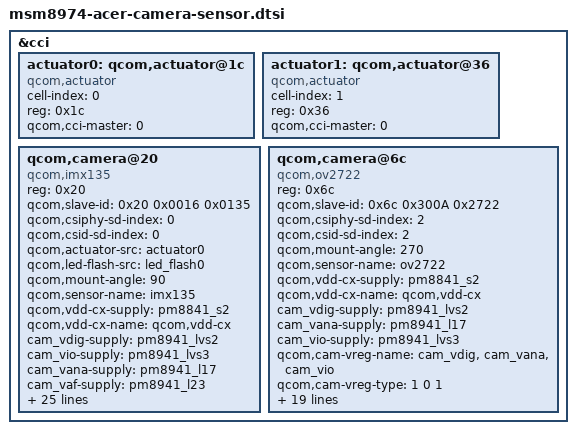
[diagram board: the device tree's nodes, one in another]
/*
 * Copyright (c) 2012-2013, The Linux Foundation. All rights reserved.
 *
 * This program is free software; you can redistribute it and/or modify
 * it under the terms of the GNU General Public License version 2 and
 * only version 2 as published by the Free Software Foundation.
 *
 * This program is distributed in the hope that it will be useful,
 * but WITHOUT ANY WARRANTY; without even the implied warranty of
 * MERCHANTABILITY or FITNESS FOR A PARTICULAR PURPOSE.  See the
 * GNU General Public License for more details.
 */

&cci {

	actuator0: qcom,actuator@1c {
		cell-index = <0>;
		reg = <0x1c>;
		compatible = "qcom,actuator";
		qcom,cci-master = <0>;
	};

	actuator1: qcom,actuator@36 {
		cell-index = <1>;
		reg = <0x36>;
		compatible = "qcom,actuator";
		qcom,cci-master = <0>;
	};

	qcom,camera@20 {
		compatible = "qcom,imx135";
		reg = <0x20>;
		qcom,slave-id = <0x20 0x0016 0x0135>;
		qcom,csiphy-sd-index = <0>;
		qcom,csid-sd-index = <0>;
		qcom,actuator-src = <&actuator0>;
		qcom,led-flash-src = <&led_flash0>;
		qcom,mount-angle = <90>;
		qcom,sensor-name = "imx135";
		qcom,vdd-cx-supply = <&pm8841_s2>;
		qcom,vdd-cx-name = "qcom,vdd-cx";
		cam_vdig-supply = <&pm8941_lvs2>;
		cam_vio-supply = <&pm8941_lvs3>;
		cam_vana-supply = <&pm8941_l17>;
		cam_vaf-supply = <&pm8941_l23>;
		cam_vif-supply = <&pm8941_l3>;
		qcom,cam-vreg-name = "cam_vdig", "cam_vio", "cam_vana",
				     "cam_vaf", "cam_vif";
		qcom,cam-vreg-type = <1 1 0 0 0>;
		qcom,cam-vreg-min-voltage = <0 0 2850000 2800000 1100000>;
		qcom,cam-vreg-max-voltage = <0 0 2850000 2800000 1225000>;
		qcom,cam-vreg-op-mode = <0 0 2850000 2800000 1100000>;
		qcom,gpio-no-mux = <0>;
		gpios = <&msmgpio 15 0>,
			<&msmgpio 89 0>;
		qcom,gpio-reset = <1>;
		qcom,gpio-req-tbl-num = <0 1>;
		qcom,gpio-req-tbl-flags = <1 0>;
		qcom,gpio-req-tbl-label = "CAMIF_MCLK",
					  "CAM_RESET1";
		qcom,gpio-set-tbl-num = <1 1>;
		qcom,gpio-set-tbl-flags = <0 2>;
		qcom,gpio-set-tbl-delay = <1000 30000>;
		qcom,csi-lane-assign = <0x4320>;
		qcom,csi-lane-mask = <0x1F>;
		qcom,sensor-position = <0>;
		qcom,sensor-mode = <1>;
		qcom,cci-master = <0>;
		status = "ok";
	};

	qcom,camera@6c {
		compatible = "qcom,ov2722";
		reg = <0x6c>;
		qcom,slave-id = <0x6c 0x300A 0x2722>;
		qcom,csiphy-sd-index = <2>;
		qcom,csid-sd-index = <2>;
		qcom,mount-angle = <270>;
		qcom,sensor-name = "ov2722";
		qcom,vdd-cx-supply = <&pm8841_s2>;
		qcom,vdd-cx-name = "qcom,vdd-cx";
		cam_vdig-supply = <&pm8941_lvs2>;
		cam_vana-supply = <&pm8941_l17>;
		cam_vio-supply = <&pm8941_lvs3>;
		qcom,cam-vreg-name = "cam_vdig", "cam_vana", "cam_vio";
		qcom,cam-vreg-type = <1 0 1>;
		qcom,cam-vreg-min-voltage = <0 2850000 0>;
		qcom,cam-vreg-max-voltage = <0 2850000 0>;
		qcom,cam-vreg-op-mode = <0 2850000 0>;
		qcom,gpio-no-mux = <0>;
		gpios = <&msmgpio 17 0>,
			<&msmgpio 18 0>,
			<&msmgpio 75 0>;
		qcom,gpio-reset = <1>;
		qcom,gpio-standby = <2>;
		qcom,gpio-req-tbl-num = <0 1 2>;
		qcom,gpio-req-tbl-flags = <1 0 2>;
		qcom,gpio-req-tbl-label = "CAMIF_MCLK",
					  "CAM_RESET1",
					  "CAM_STANDBY1";
		qcom,gpio-set-tbl-num = <1 1 2 2>;
		qcom,gpio-set-tbl-flags = <0 2 2 0>;
		qcom,gpio-set-tbl-delay = <5000 5000 5000 5000>;
		qcom,csi-lane-assign = <0x4320>;
		qcom,csi-lane-mask = <0x3>;
		qcom,sensor-position = <1>;
		qcom,sensor-mode = <1>;
		qcom,cci-master = <0>;
		status = "ok";
	};
};
